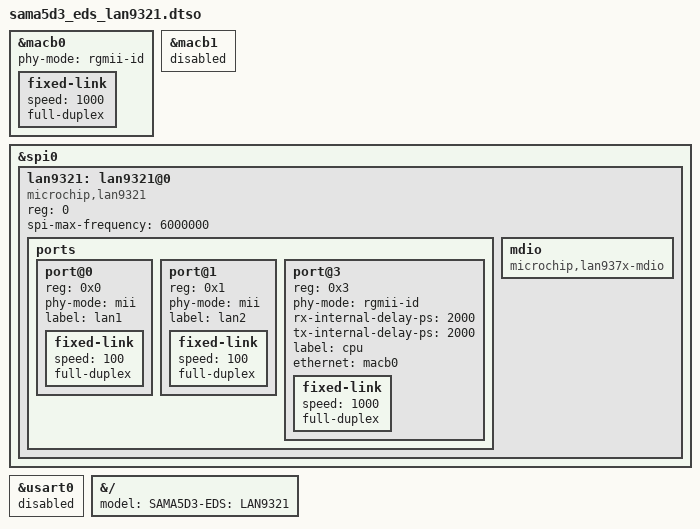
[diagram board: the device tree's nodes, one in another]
// SPDX-License-Identifier: (GPL-2.0+ OR MIT)
/*
 * sama5d3_eds_lan9374.dtso - Device Tree file for SAMA5D3 EDS board
 * overlay blob for the LAN9374 RGMII addon board.
 *
 * Copyright (C) 2022 Microchip Technology, Inc. and its subsidiaries
 *   Author:	 2022 Jerry Ray <jerry.ray@microchip.com>
 *
 * 8-Port 100BASE-T1 Gigabit Ethernet Switch
 * https://www.microchip.com/en-us/product/LAN9374
 *
 */
/dts-v1/;
/plugin/;

#include "dt-bindings/gpio/gpio.h"
#include "dt-bindings/interrupt-controller/irq.h"
#include "dt-bindings/pinctrl/at91.h"

&macb0 {
	phy-mode = "rgmii-id";
	status = "okay";

	fixed-link {
		speed = <1000>;
		full-duplex;
	};
};

&macb1 {
	status = "disabled";
};

&spi0 {
	#address-cells = <1>;
	#size-cells = <0>;
	status = "okay";

	lan9321: lan9321@0 {
		compatible = "microchip,lan9321";
		reg = <0>;
		spi-max-frequency = <6000000>;
		status = "okay";
		ports {
			#address-cells = <1>;
		      	#size-cells = <0>;
		      	port@0 {
				reg = <0x0>;
				//phy-handle = <&t1phy0>;
				phy-mode = "mii";
				label = "lan1";
				fixed-link {
					   speed = <100>;
					   full-duplex;
				};				
			};
			port@1 {
				reg = <0x1>;
				//phy-handle = <&t1phy1>;
				phy-mode = "mii";
				label = "lan2";
				fixed-link {
					   speed = <100>;
					   full-duplex;
				};				
			};
			port@3 {
				reg = <0x3>;
				phy-mode = "rgmii-id";
				rx-internal-delay-ps = <2000>;
				tx-internal-delay-ps = <2000>;				
				label = "cpu";
				ethernet = <&macb0>;
				fixed-link {
					   speed = <1000>;
					   full-duplex;
				};
			};
		};
		mdio {
			#address-cells = <1>;
			#size-cells = <0>;
			compatible = "microchip,lan937x-mdio";
						
			// t1phy0: ethernet-phy@0{
			// 	reg = <0x0>;
			// };
			// t1phy1: ethernet-phy@1{
			// 	reg = <0x1>;
			// };
		};
	};
};

&usart0 {
	status = "disabled";    /* Conflicts with using pioD 18 as GPIO */
};

&{/} {
	model = "SAMA5D3-EDS: LAN9321";
};
